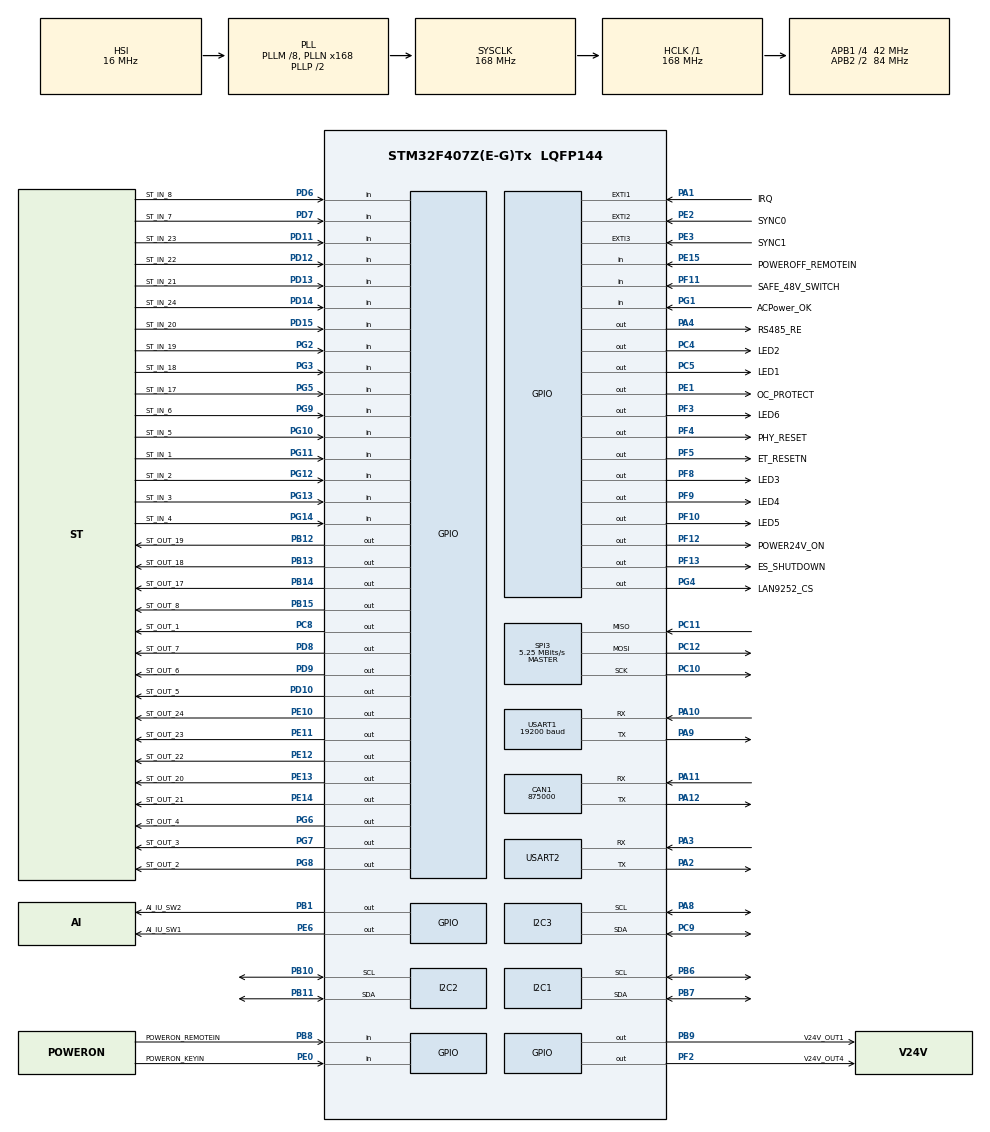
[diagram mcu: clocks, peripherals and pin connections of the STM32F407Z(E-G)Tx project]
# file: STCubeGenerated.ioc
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CAN1.CalculateBaudRate=875000
CAN1.CalculateTimeBit=1142
CAN1.CalculateTimeQuantum=380.95238095238096
Mcu.Family=STM32F4
Mcu.Name=STM32F407Z(E-G)Tx
Mcu.Package=LQFP144
NVIC.CAN1_RX0_IRQn=true\:4\:0\:true\:false\:true\:true\:true
NVIC.EXTI1_IRQn=true\:6\:0\:true\:false\:true\:true\:true
NVIC.EXTI2_IRQn=true\:6\:1\:true\:false\:true\:true\:true
NVIC.EXTI3_IRQn=true\:7\:0\:true\:false\:true\:true\:true
NVIC.PriorityGroup=NVIC_PRIORITYGROUP_3
NVIC.USART1_IRQn=true\:3\:1\:true\:false\:true\:true\:true
NVIC.USART2_IRQn=true\:3\:0\:true\:false\:true\:true\:true
PA1.GPIO_Label=IRQ
PA1.GPIO_ModeDefaultEXTI=GPIO_MODE_IT_FALLING
PA1.Signal=GPXTI1
PA10.GPIO_PuPd=GPIO_NOPULL
PA10.GPIO_Speed=GPIO_SPEED_FREQ_HIGH
PA10.Mode=Asynchronous
PA10.Signal=USART1_RX
PA11.Mode=CAN_Activate
PA11.Signal=CAN1_RX
PA12.Mode=CAN_Activate
PA12.Signal=CAN1_TX
PA2.Mode=Asynchronous
PA2.Signal=USART2_TX
PA3.Mode=Asynchronous
PA3.Signal=USART2_RX
PA4.GPIO_Label=RS485_RE
PA4.GPIO_ModeDefaultOutputPP=GPIO_MODE_OUTPUT_PP
PA4.GPIO_PuPd=GPIO_PULLUP
PA4.GPIO_Speed=GPIO_SPEED_FREQ_VERY_HIGH
PA4.PinState=GPIO_PIN_SET
PA4.Signal=GPIO_Output
PA8.Mode=I2C
PA8.Signal=I2C3_SCL
PA9.GPIO_PuPd=GPIO_NOPULL
PA9.GPIO_Speed=GPIO_SPEED_FREQ_HIGH
PA9.Mode=Asynchronous
PA9.Signal=USART1_TX
PB1.GPIO_Label=AI_IU_SW2
PB1.Signal=GPIO_Output
PB10.Mode=I2C
PB10.Signal=I2C2_SCL
PB11.Mode=I2C
PB11.Signal=I2C2_SDA
PB12.GPIO_Label=ST_OUT_19
PB12.GPIO_ModeDefaultOutputPP=GPIO_MODE_OUTPUT_OD
PB12.GPIO_PuPd=GPIO_NOPULL
PB12.PinState=GPIO_PIN_SET
PB12.Signal=GPIO_Output
PB13.GPIO_Label=ST_OUT_18
PB13.GPIO_ModeDefaultOutputPP=GPIO_MODE_OUTPUT_OD
PB13.GPIO_PuPd=GPIO_NOPULL
PB13.PinState=GPIO_PIN_SET
PB13.Signal=GPIO_Output
PB14.GPIO_Label=ST_OUT_17
PB14.GPIO_ModeDefaultOutputPP=GPIO_MODE_OUTPUT_OD
PB14.GPIO_PuPd=GPIO_NOPULL
PB14.PinState=GPIO_PIN_SET
PB14.Signal=GPIO_Output
PB15.GPIO_Label=ST_OUT_8
PB15.GPIO_ModeDefaultOutputPP=GPIO_MODE_OUTPUT_OD
PB15.GPIO_PuPd=GPIO_NOPULL
PB15.PinState=GPIO_PIN_SET
PB15.Signal=GPIO_Output
PB6.Mode=I2C
PB6.Signal=I2C1_SCL
PB7.Mode=I2C
PB7.Signal=I2C1_SDA
PB8.GPIO_Label=POWERON_REMOTEIN
PB8.Signal=GPIO_Input
PB9.GPIO_Label=V24V_OUT1
PB9.Signal=GPIO_Output
PC10.Mode=Full_Duplex_Master
PC10.Signal=SPI3_SCK
PC11.Mode=Full_Duplex_Master
PC11.Signal=SPI3_MISO
PC12.Mode=Full_Duplex_Master
PC12.Signal=SPI3_MOSI
PC4.GPIO_Label=LED2
PC4.GPIO_ModeDefaultOutputPP=GPIO_MODE_OUTPUT_OD
PC4.GPIO_PuPd=GPIO_NOPULL
PC4.PinState=GPIO_PIN_SET
PC4.Signal=GPIO_Output
PC5.GPIO_Label=LED1
PC5.GPIO_ModeDefaultOutputPP=GPIO_MODE_OUTPUT_OD
PC5.GPIO_PuPd=GPIO_NOPULL
PC5.PinState=GPIO_PIN_SET
PC5.Signal=GPIO_Output
PC8.GPIO_Label=ST_OUT_1
PC8.GPIO_ModeDefaultOutputPP=GPIO_MODE_OUTPUT_OD
PC8.GPIO_PuPd=GPIO_NOPULL
PC8.PinState=GPIO_PIN_SET
PC8.Signal=GPIO_Output
PC9.Mode=I2C
PC9.Signal=I2C3_SDA
PD10.GPIO_Label=ST_OUT_5
PD10.GPIO_ModeDefaultOutputPP=GPIO_MODE_OUTPUT_OD
PD10.GPIO_PuPd=GPIO_NOPULL
PD10.PinState=GPIO_PIN_SET
PD10.Signal=GPIO_Output
PD11.GPIO_Label=ST_IN_23
PD11.Signal=GPIO_Input
PD12.GPIO_Label=ST_IN_22
PD12.Signal=GPIO_Input
PD13.GPIO_Label=ST_IN_21
PD13.Signal=GPIO_Input
PD14.GPIO_Label=ST_IN_24
PD14.Signal=GPIO_Input
PD15.GPIO_Label=ST_IN_20
PD15.Signal=GPIO_Input
PD6.GPIO_Label=ST_IN_8
PD6.Signal=GPIO_Input
PD7.GPIO_Label=ST_IN_7
PD7.Signal=GPIO_Input
PD8.GPIO_Label=ST_OUT_7
PD8.GPIO_ModeDefaultOutputPP=GPIO_MODE_OUTPUT_OD
PD8.GPIO_PuPd=GPIO_NOPULL
PD8.PinState=GPIO_PIN_SET
PD8.Signal=GPIO_Output
PD9.GPIO_Label=ST_OUT_6
PD9.GPIO_ModeDefaultOutputPP=GPIO_MODE_OUTPUT_OD
PD9.GPIO_PuPd=GPIO_NOPULL
PD9.PinState=GPIO_PIN_SET
PD9.Signal=GPIO_Output
PE0.GPIO_Label=POWERON_KEYIN
PE0.Signal=GPIO_Input
PE1.GPIO_Label=OC_PROTECT
PE1.Signal=GPIO_Output
PE10.GPIO_Label=ST_OUT_24
PE10.GPIO_ModeDefaultOutputPP=GPIO_MODE_OUTPUT_OD
PE10.GPIO_PuPd=GPIO_NOPULL
PE10.PinState=GPIO_PIN_SET
PE10.Signal=GPIO_Output
PE11.GPIO_Label=ST_OUT_23
PE11.GPIO_ModeDefaultOutputPP=GPIO_MODE_OUTPUT_OD
PE11.GPIO_PuPd=GPIO_NOPULL
PE11.PinState=GPIO_PIN_SET
PE11.Signal=GPIO_Output
PE12.GPIO_Label=ST_OUT_22
PE12.GPIO_ModeDefaultOutputPP=GPIO_MODE_OUTPUT_OD
PE12.GPIO_PuPd=GPIO_NOPULL
PE12.PinState=GPIO_PIN_SET
PE12.Signal=GPIO_Output
PE13.GPIO_Label=ST_OUT_20
PE13.GPIO_ModeDefaultOutputPP=GPIO_MODE_OUTPUT_OD
PE13.GPIO_PuPd=GPIO_NOPULL
PE13.PinState=GPIO_PIN_SET
PE13.Signal=GPIO_Output
PE14.GPIO_Label=ST_OUT_21
PE14.GPIO_ModeDefaultOutputPP=GPIO_MODE_OUTPUT_OD
PE14.GPIO_PuPd=GPIO_NOPULL
PE14.PinState=GPIO_PIN_SET
PE14.Signal=GPIO_Output
PE15.GPIO_Label=POWEROFF_REMOTEIN
PE15.Signal=GPIO_Input
PE2.GPIO_Label=SYNC0
PE2.GPIO_ModeDefaultEXTI=GPIO_MODE_IT_FALLING
PE2.Signal=GPXTI2
PE3.GPIO_Label=SYNC1
PE3.GPIO_ModeDefaultEXTI=GPIO_MODE_IT_FALLING
PE3.Signal=GPXTI3
PE6.GPIO_Label=AI_IU_SW1
PE6.Signal=GPIO_Output
PF10.GPIO_Label=LED5
PF10.GPIO_ModeDefaultOutputPP=GPIO_MODE_OUTPUT_OD
PF10.GPIO_PuPd=GPIO_NOPULL
PF10.PinState=GPIO_PIN_SET
PF10.Signal=GPIO_Output
PF11.GPIO_Label=SAFE_48V_SWITCH
PF11.Signal=GPIO_Input
PF12.GPIO_Label=POWER24V_ON
PF12.Signal=GPIO_Output
PF13.GPIO_Label=ES_SHUTDOWN
PF13.PinState=GPIO_PIN_SET
PF13.Signal=GPIO_Output
PF2.GPIO_Label=V24V_OUT4
PF2.Signal=GPIO_Output
PF3.GPIO_Label=LED6
PF3.GPIO_ModeDefaultOutputPP=GPIO_MODE_OUTPUT_OD
PF3.GPIO_PuPd=GPIO_NOPULL
PF3.PinState=GPIO_PIN_SET
PF3.Signal=GPIO_Output
PF4.GPIO_Label=PHY_RESET
PF4.GPIO_ModeDefaultOutputPP=GPIO_MODE_OUTPUT_OD
PF4.GPIO_PuPd=GPIO_NOPULL
PF4.PinState=GPIO_PIN_SET
PF4.Signal=GPIO_Output
PF5.GPIO_Label=ET_RESETN
PF5.GPIO_ModeDefaultOutputPP=GPIO_MODE_OUTPUT_OD
PF5.GPIO_PuPd=GPIO_NOPULL
PF5.PinState=GPIO_PIN_SET
PF5.Signal=GPIO_Output
PF8.GPIO_Label=LED3
PF8.GPIO_ModeDefaultOutputPP=GPIO_MODE_OUTPUT_OD
PF8.GPIO_PuPd=GPIO_NOPULL
PF8.PinState=GPIO_PIN_SET
PF8.Signal=GPIO_Output
PF9.GPIO_Label=LED4
PF9.GPIO_ModeDefaultOutputPP=GPIO_MODE_OUTPUT_OD
PF9.GPIO_PuPd=GPIO_NOPULL
PF9.PinState=GPIO_PIN_SET
PF9.Signal=GPIO_Output
PG1.GPIO_Label=ACPower_OK
PG1.Signal=GPIO_Input
PG10.GPIO_Label=ST_IN_5
PG10.Signal=GPIO_Input
PG11.GPIO_Label=ST_IN_1
PG11.Signal=GPIO_Input
PG12.GPIO_Label=ST_IN_2
PG12.Signal=GPIO_Input
PG13.GPIO_Label=ST_IN_3
PG13.Signal=GPIO_Input
PG14.GPIO_Label=ST_IN_4
PG14.Signal=GPIO_Input
PG2.GPIO_Label=ST_IN_19
PG2.Signal=GPIO_Input
PG3.GPIO_Label=ST_IN_18
PG3.Signal=GPIO_Input
PG4.GPIO_Label=LAN9252_CS
PG4.GPIO_PuPd=GPIO_PULLUP
PG4.GPIO_Speed=GPIO_SPEED_FREQ_VERY_HIGH
PG4.PinState=GPIO_PIN_SET
PG4.Signal=GPIO_Output
PG5.GPIO_Label=ST_IN_17
PG5.Signal=GPIO_Input
PG6.GPIO_Label=ST_OUT_4
PG6.GPIO_ModeDefaultOutputPP=GPIO_MODE_OUTPUT_OD
PG6.GPIO_PuPd=GPIO_NOPULL
PG6.PinState=GPIO_PIN_SET
PG6.Signal=GPIO_Output
PG7.GPIO_Label=ST_OUT_3
PG7.GPIO_ModeDefaultOutputPP=GPIO_MODE_OUTPUT_OD
PG7.GPIO_PuPd=GPIO_NOPULL
PG7.PinState=GPIO_PIN_SET
PG7.Signal=GPIO_Output
PG8.GPIO_Label=ST_OUT_2
PG8.GPIO_ModeDefaultOutputPP=GPIO_MODE_OUTPUT_OD
PG8.GPIO_PuPd=GPIO_NOPULL
PG8.PinState=GPIO_PIN_SET
PG8.Signal=GPIO_Output
PG9.GPIO_Label=ST_IN_6
PG9.Signal=GPIO_Input
PH0-OSC_IN.Mode=HSE-External-Oscillator
PH0-OSC_IN.Signal=RCC_OSC_IN
PH1-OSC_OUT.Mode=HSE-External-Oscillator
PH1-OSC_OUT.Signal=RCC_OSC_OUT
ProjectManager.HeapSize=0x200
ProjectManager.StackSize=0x400
ProjectManager.TargetToolchain=MDK-ARM V5
RCC.48MHZClocksFreq_Value=84000000
RCC.AHBFreq_Value=168000000
RCC.APB1CLKDivider=RCC_HCLK_DIV4
RCC.APB1Freq_Value=42000000
RCC.APB1TimFreq_Value=84000000
RCC.APB2CLKDivider=RCC_HCLK_DIV2
RCC.APB2Freq_Value=84000000
RCC.APB2TimFreq_Value=168000000
RCC.CortexFreq_Value=168000000
RCC.HCLKFreq_Value=168000000
RCC.HSE_VALUE=8000000
RCC.HSI_VALUE=16000000
RCC.LSE_VALUE=32768
RCC.PLLM=8
RCC.PLLN=168
RCC.SYSCLKFreq_VALUE=168000000
RCC.SYSCLKSource=RCC_SYSCLKSOURCE_PLLCLK
RCC.VCOOutputFreq_Value=336000000
SPI3.BaudRatePrescaler=SPI_BAUDRATEPRESCALER_8
SPI3.CLKPhase=SPI_PHASE_1EDGE
SPI3.CLKPolarity=SPI_POLARITY_LOW
SPI3.CalculateBaudRate=5.25 MBits/s
SPI3.DataSize=SPI_DATASIZE_8BIT
SPI3.Direction=SPI_DIRECTION_2LINES
SPI3.Mode=SPI_MODE_MASTER
SPI3.TIMode=SPI_TIMODE_DISABLE
SPI3.VirtualType=VM_MASTER
USART1.BaudRate=19200
USART1.VirtualMode=VM_ASYNC
USART2.VirtualMode=VM_ASYNC
board=custom

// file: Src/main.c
/* USER CODE BEGIN Header */
/**
  ******************************************************************************
  * @file           : main.c
  * @brief          : Main program body
  ******************************************************************************
  * @attention
  *
  * Copyright (c) 2022 STMicroelectronics.
  * All rights reserved.
  *
  * This software is licensed under terms that can be found in the LICENSE file
  * in the root directory of this software component.
  * If no LICENSE file comes with this software, it is provided AS-IS.
  *
  ******************************************************************************
  */
/* USER CODE END Header */
#include "main.h"

/* USER CODE BEGIN Includes */
#include "ADS1115Driver.h"
#include "Command.h"
#include "KeyIn.h"
#include "PowerMenu.h"
#include "KeyIn.h"

/* USER CODE END Includes */

CAN_HandleTypeDef hcan1;

I2C_HandleTypeDef hi2c1;
I2C_HandleTypeDef hi2c2;
I2C_HandleTypeDef hi2c3;

SPI_HandleTypeDef hspi3;

UART_HandleTypeDef huart1;
UART_HandleTypeDef huart2;

void SystemClock_Config(void);
static void MX_GPIO_Init(void);
static void MX_SPI3_Init(void);
static void MX_CAN1_Init(void);
static void MX_I2C1_Init(void);
static void MX_I2C2_Init(void);
static void MX_I2C3_Init(void);
static void MX_USART1_UART_Init(void);
static void MX_USART2_UART_Init(void);
/* USER CODE BEGIN PFP */

void PHY_Init(void);
/* USER CODE END PFP */

int main(void)
{

  /* MCU Configuration--------------------------------------------------------*/

  /* Reset of all peripherals, Initializes the Flash interface and the Systick. */
  HAL_Init();

  /* Configure the system clock */
  SystemClock_Config();

  /* Initialize all configured peripherals */
  MX_GPIO_Init();
  MX_SPI3_Init();
  MX_CAN1_Init();
  MX_I2C1_Init();
  MX_I2C2_Init();
  MX_I2C3_Init();
  MX_USART1_UART_Init();
  MX_USART2_UART_Init();
  /* USER CODE BEGIN 2 */
    EcatHspiPtr = &hspi3;
		I2C_Ptr_24V = &hi2c1;
		I2C_Ptr_48V_NTC = &hi2c3;
		I2C_Ptr_AI = &hi2c2;
		Uart_HandlePtr = &huart1;
//		Udma_UartRx_HandlePtr = &hdma_usart1_rx;
//		Udma_Uarttx_HandlePtr = &hdma_usart1_tx;
//    LAN9252_Init();
//    MainInit();
//    bRunApplication = TRUE;
//		PHY_Init();
//		HAL_GPIO_WritePin(OC_PROTECT_GPIO_Port, OC_PROTECT_Pin, GPIO_PIN_RESET);
//		HAL_GPIO_WritePin(V24V_OUT1_GPIO_Port, V24V_OUT1_Pin, GPIO_PIN_SET);
//		HAL_GPIO_WritePin(ES_SHUTDOWN_GPIO_Port, ES_SHUTDOWN_Pin, GPIO_PIN_SET);
		if (HAL_UARTEx_ReceiveToIdle_IT(&huart1, PowerCommandRxBuffer, POWER_COMMAND_TXRX_BUFFER_SIZE) != HAL_OK)
		{
			Error_Handler();
		}
		ADS1115_Driver_Initilization();
		Power_Command_Initilization();
  /* USER CODE END 2 */

  /* Infinite loop */
  /* USER CODE BEGIN WHILE */
  while (1)
  {
//		MainLoop();
	  work_mode_operation();
		ADS1115_Driver_MainLoop();
		KeyScan(power_manage.work_mode);
		Power_Command_Main_Loop();

    /* USER CODE END WHILE */

  }
}

void SystemClock_Config(void)
{
  RCC_OscInitTypeDef RCC_OscInitStruct = {0};
  RCC_ClkInitTypeDef RCC_ClkInitStruct = {0};

  /** Configure the main internal regulator output voltage
  */
  __HAL_RCC_PWR_CLK_ENABLE();
  __HAL_PWR_VOLTAGESCALING_CONFIG(PWR_REGULATOR_VOLTAGE_SCALE1);
  /** Initializes the RCC Oscillators according to the specified parameters
  * in the RCC_OscInitTypeDef structure.
  */
  RCC_OscInitStruct.OscillatorType = RCC_OSCILLATORTYPE_HSI;
  RCC_OscInitStruct.HSIState = RCC_HSI_ON;
  RCC_OscInitStruct.HSICalibrationValue = RCC_HSICALIBRATION_DEFAULT;
  RCC_OscInitStruct.PLL.PLLState = RCC_PLL_ON;
  RCC_OscInitStruct.PLL.PLLSource = RCC_PLLSOURCE_HSI;
  RCC_OscInitStruct.PLL.PLLM = 8;
  RCC_OscInitStruct.PLL.PLLN = 168;
  RCC_OscInitStruct.PLL.PLLP = RCC_PLLP_DIV2;
  RCC_OscInitStruct.PLL.PLLQ = 4;
  if (HAL_RCC_OscConfig(&RCC_OscInitStruct) != HAL_OK)
  {
    Error_Handler();
  }
  /** Initializes the CPU, AHB and APB buses clocks
  */
  RCC_ClkInitStruct.ClockType = RCC_CLOCKTYPE_HCLK|RCC_CLOCKTYPE_SYSCLK
                              |RCC_CLOCKTYPE_PCLK1|RCC_CLOCKTYPE_PCLK2;
  RCC_ClkInitStruct.SYSCLKSource = RCC_SYSCLKSOURCE_PLLCLK;
  RCC_ClkInitStruct.AHBCLKDivider = RCC_SYSCLK_DIV1;
  RCC_ClkInitStruct.APB1CLKDivider = RCC_HCLK_DIV4;
  RCC_ClkInitStruct.APB2CLKDivider = RCC_HCLK_DIV2;

  if (HAL_RCC_ClockConfig(&RCC_ClkInitStruct, FLASH_LATENCY_5) != HAL_OK)
  {
    Error_Handler();
  }
}

static void MX_CAN1_Init(void)
{

  hcan1.Instance = CAN1;
  hcan1.Init.Prescaler = 16;
  hcan1.Init.Mode = CAN_MODE_NORMAL;
  hcan1.Init.SyncJumpWidth = CAN_SJW_1TQ;
  hcan1.Init.TimeSeg1 = CAN_BS1_1TQ;
  hcan1.Init.TimeSeg2 = CAN_BS2_1TQ;
  hcan1.Init.TimeTriggeredMode = DISABLE;
  hcan1.Init.AutoBusOff = DISABLE;
  hcan1.Init.AutoWakeUp = DISABLE;
  hcan1.Init.AutoRetransmission = DISABLE;
  hcan1.Init.ReceiveFifoLocked = DISABLE;
  hcan1.Init.TransmitFifoPriority = DISABLE;
  if (HAL_CAN_Init(&hcan1) != HAL_OK)
  {
    Error_Handler();
  }

}

static void MX_I2C1_Init(void)
{

  hi2c1.Instance = I2C1;
  hi2c1.Init.ClockSpeed = 100000;
  hi2c1.Init.DutyCycle = I2C_DUTYCYCLE_2;
  hi2c1.Init.OwnAddress1 = 0;
  hi2c1.Init.AddressingMode = I2C_ADDRESSINGMODE_7BIT;
  hi2c1.Init.DualAddressMode = I2C_DUALADDRESS_DISABLE;
  hi2c1.Init.OwnAddress2 = 0;
  hi2c1.Init.GeneralCallMode = I2C_GENERALCALL_DISABLE;
  hi2c1.Init.NoStretchMode = I2C_NOSTRETCH_DISABLE;
  if (HAL_I2C_Init(&hi2c1) != HAL_OK)
  {
    Error_Handler();
  }

}

static void MX_I2C2_Init(void)
{

  hi2c2.Instance = I2C2;
  hi2c2.Init.ClockSpeed = 100000;
  hi2c2.Init.DutyCycle = I2C_DUTYCYCLE_2;
  hi2c2.Init.OwnAddress1 = 0;
  hi2c2.Init.AddressingMode = I2C_ADDRESSINGMODE_7BIT;
  hi2c2.Init.DualAddressMode = I2C_DUALADDRESS_DISABLE;
  hi2c2.Init.OwnAddress2 = 0;
  hi2c2.Init.GeneralCallMode = I2C_GENERALCALL_DISABLE;
  hi2c2.Init.NoStretchMode = I2C_NOSTRETCH_DISABLE;
  if (HAL_I2C_Init(&hi2c2) != HAL_OK)
  {
    Error_Handler();
  }

}

static void MX_I2C3_Init(void)
{

  hi2c3.Instance = I2C3;
  hi2c3.Init.ClockSpeed = 100000;
  hi2c3.Init.DutyCycle = I2C_DUTYCYCLE_2;
  hi2c3.Init.OwnAddress1 = 0;
  hi2c3.Init.AddressingMode = I2C_ADDRESSINGMODE_7BIT;
  hi2c3.Init.DualAddressMode = I2C_DUALADDRESS_DISABLE;
  hi2c3.Init.OwnAddress2 = 0;
  hi2c3.Init.GeneralCallMode = I2C_GENERALCALL_DISABLE;
  hi2c3.Init.NoStretchMode = I2C_NOSTRETCH_DISABLE;
  if (HAL_I2C_Init(&hi2c3) != HAL_OK)
  {
    Error_Handler();
  }

}

static void MX_SPI3_Init(void)
{

  /* SPI3 parameter configuration*/
  hspi3.Instance = SPI3;
  hspi3.Init.Mode = SPI_MODE_MASTER;
  hspi3.Init.Direction = SPI_DIRECTION_2LINES;
  hspi3.Init.DataSize = SPI_DATASIZE_8BIT;
  hspi3.Init.CLKPolarity = SPI_POLARITY_LOW;
  hspi3.Init.CLKPhase = SPI_PHASE_1EDGE;
  hspi3.Init.NSS = SPI_NSS_SOFT;
  hspi3.Init.BaudRatePrescaler = SPI_BAUDRATEPRESCALER_8;
  hspi3.Init.FirstBit = SPI_FIRSTBIT_MSB;
  hspi3.Init.TIMode = SPI_TIMODE_DISABLE;
  hspi3.Init.CRCCalculation = SPI_CRCCALCULATION_DISABLE;
  hspi3.Init.CRCPolynomial = 10;
  if (HAL_SPI_Init(&hspi3) != HAL_OK)
  {
    Error_Handler();
  }
  /* USER CODE BEGIN SPI3_Init 2 */
//	hspi3.pTxBuffPtr = EcatSpiWriteBuffer;
//	hspi3.pRxBuffPtr = EcatSpiReadBuffer;
//	hspi3.RxXferSize = SPI_BUFFER_SIZE;
//	hspi3.TxXferSize = SPI_BUFFER_SIZE;
//	hspi3.RxXferCount = 0u;
//	hspi3.TxXferCount = 0u;
  /* USER CODE END SPI3_Init 2 */

}

static void MX_USART1_UART_Init(void)
{

  huart1.Instance = USART1;
  huart1.Init.BaudRate = 19200;
  huart1.Init.WordLength = UART_WORDLENGTH_8B;
  huart1.Init.StopBits = UART_STOPBITS_1;
  huart1.Init.Parity = UART_PARITY_NONE;
  huart1.Init.Mode = UART_MODE_TX_RX;
  huart1.Init.HwFlowCtl = UART_HWCONTROL_NONE;
  huart1.Init.OverSampling = UART_OVERSAMPLING_16;
  if (HAL_UART_Init(&huart1) != HAL_OK)
  {
    Error_Handler();
  }

}

static void MX_USART2_UART_Init(void)
{

  huart2.Instance = USART2;
  huart2.Init.BaudRate = 115200;
  huart2.Init.WordLength = UART_WORDLENGTH_8B;
  huart2.Init.StopBits = UART_STOPBITS_1;
  huart2.Init.Parity = UART_PARITY_NONE;
  huart2.Init.Mode = UART_MODE_TX_RX;
  huart2.Init.HwFlowCtl = UART_HWCONTROL_NONE;
  huart2.Init.OverSampling = UART_OVERSAMPLING_16;
  if (HAL_UART_Init(&huart2) != HAL_OK)
  {
    Error_Handler();
  }

}

static void MX_GPIO_Init(void)
{
  GPIO_InitTypeDef GPIO_InitStruct = {0};

  /* GPIO Ports Clock Enable */
  __HAL_RCC_GPIOE_CLK_ENABLE();
  __HAL_RCC_GPIOF_CLK_ENABLE();
  __HAL_RCC_GPIOH_CLK_ENABLE();
  __HAL_RCC_GPIOA_CLK_ENABLE();
  __HAL_RCC_GPIOC_CLK_ENABLE();
  __HAL_RCC_GPIOB_CLK_ENABLE();
  __HAL_RCC_GPIOG_CLK_ENABLE();
  __HAL_RCC_GPIOD_CLK_ENABLE();

  /*Configure GPIO pin Output Level */
  HAL_GPIO_WritePin(GPIOE, AI_IU_SW1_Pin|OC_PROTECT_Pin, GPIO_PIN_RESET);

  /*Configure GPIO pin Output Level */
  HAL_GPIO_WritePin(GPIOF, V24V_OUT4_Pin|POWER24V_ON_Pin, GPIO_PIN_RESET);

  /*Configure GPIO pin Output Level */
  HAL_GPIO_WritePin(GPIOF, LED6_Pin|PHY_RESET_Pin|ET_RESETN_Pin|LED3_Pin
                          |LED4_Pin|LED5_Pin|ES_SHUTDOWN_Pin, GPIO_PIN_SET);

  /*Configure GPIO pin Output Level */
  HAL_GPIO_WritePin(RS485_RE_GPIO_Port, RS485_RE_Pin, GPIO_PIN_SET);

  /*Configure GPIO pin Output Level */
  HAL_GPIO_WritePin(GPIOC, LED2_Pin|LED1_Pin|ST_OUT_1_Pin, GPIO_PIN_SET);

  /*Configure GPIO pin Output Level */
  HAL_GPIO_WritePin(GPIOB, AI_IU_SW2_Pin|V24V_OUT1_Pin, GPIO_PIN_RESET);

  /*Configure GPIO pin Output Level */
  HAL_GPIO_WritePin(GPIOE, ST_OUT_24_Pin|ST_OUT_23_Pin|ST_OUT_22_Pin|ST_OUT_20_Pin
                          |ST_OUT_21_Pin, GPIO_PIN_SET);

  /*Configure GPIO pin Output Level */
  HAL_GPIO_WritePin(GPIOB, ST_OUT_19_Pin|ST_OUT_18_Pin|ST_OUT_17_Pin|ST_OUT_8_Pin, GPIO_PIN_SET);

  /*Configure GPIO pin Output Level */
  HAL_GPIO_WritePin(GPIOD, ST_OUT_7_Pin|ST_OUT_6_Pin|ST_OUT_5_Pin, GPIO_PIN_SET);

  /*Configure GPIO pin Output Level */
  HAL_GPIO_WritePin(GPIOG, LAN9252_CS_Pin|ST_OUT_4_Pin|ST_OUT_3_Pin|ST_OUT_2_Pin, GPIO_PIN_SET);

  /*Configure GPIO pins : SYNC0_Pin SYNC1_Pin */
  GPIO_InitStruct.Pin = SYNC0_Pin|SYNC1_Pin;
  GPIO_InitStruct.Mode = GPIO_MODE_IT_FALLING;
  GPIO_InitStruct.Pull = GPIO_NOPULL;
  HAL_GPIO_Init(GPIOE, &GPIO_InitStruct);

  /*Configure GPIO pins : AI_IU_SW1_Pin OC_PROTECT_Pin */
  GPIO_InitStruct.Pin = AI_IU_SW1_Pin|OC_PROTECT_Pin;
  GPIO_InitStruct.Mode = GPIO_MODE_OUTPUT_PP;
  GPIO_InitStruct.Pull = GPIO_NOPULL;
  GPIO_InitStruct.Speed = GPIO_SPEED_FREQ_LOW;
  HAL_GPIO_Init(GPIOE, &GPIO_InitStruct);

  /*Configure GPIO pins : V24V_OUT4_Pin POWER24V_ON_Pin ES_SHUTDOWN_Pin */
  GPIO_InitStruct.Pin = V24V_OUT4_Pin|POWER24V_ON_Pin|ES_SHUTDOWN_Pin;
  GPIO_InitStruct.Mode = GPIO_MODE_OUTPUT_PP;
  GPIO_InitStruct.Pull = GPIO_NOPULL;
  GPIO_InitStruct.Speed = GPIO_SPEED_FREQ_LOW;
  HAL_GPIO_Init(GPIOF, &GPIO_InitStruct);

  /*Configure GPIO pins : LED6_Pin PHY_RESET_Pin ET_RESETN_Pin LED3_Pin
                           LED4_Pin LED5_Pin */
  GPIO_InitStruct.Pin = LED6_Pin|PHY_RESET_Pin|ET_RESETN_Pin|LED3_Pin
                          |LED4_Pin|LED5_Pin;
  GPIO_InitStruct.Mode = GPIO_MODE_OUTPUT_OD;
  GPIO_InitStruct.Pull = GPIO_NOPULL;
  GPIO_InitStruct.Speed = GPIO_SPEED_FREQ_LOW;
  HAL_GPIO_Init(GPIOF, &GPIO_InitStruct);

  /*Configure GPIO pin : IRQ_Pin */
  GPIO_InitStruct.Pin = IRQ_Pin;
  GPIO_InitStruct.Mode = GPIO_MODE_IT_FALLING;
  GPIO_InitStruct.Pull = GPIO_NOPULL;
  HAL_GPIO_Init(IRQ_GPIO_Port, &GPIO_InitStruct);

  /*Configure GPIO pin : RS485_RE_Pin */
  GPIO_InitStruct.Pin = RS485_RE_Pin;
  GPIO_InitStruct.Mode = GPIO_MODE_OUTPUT_PP;
  GPIO_InitStruct.Pull = GPIO_PULLUP;
  GPIO_InitStruct.Speed = GPIO_SPEED_FREQ_VERY_HIGH;
  HAL_GPIO_Init(RS485_RE_GPIO_Port, &GPIO_InitStruct);

  /*Configure GPIO pins : LED2_Pin LED1_Pin ST_OUT_1_Pin */
  GPIO_InitStruct.Pin = LED2_Pin|LED1_Pin|ST_OUT_1_Pin;
  GPIO_InitStruct.Mode = GPIO_MODE_OUTPUT_OD;
  GPIO_InitStruct.Pull = GPIO_NOPULL;
  GPIO_InitStruct.Speed = GPIO_SPEED_FREQ_LOW;
  HAL_GPIO_Init(GPIOC, &GPIO_InitStruct);

  /*Configure GPIO pins : AI_IU_SW2_Pin V24V_OUT1_Pin */
  GPIO_InitStruct.Pin = AI_IU_SW2_Pin|V24V_OUT1_Pin;
  GPIO_InitStruct.Mode = GPIO_MODE_OUTPUT_PP;
  GPIO_InitStruct.Pull = GPIO_NOPULL;
  GPIO_InitStruct.Speed = GPIO_SPEED_FREQ_LOW;
  HAL_GPIO_Init(GPIOB, &GPIO_InitStruct);

  /*Configure GPIO pin : SAFE_48V_SWITCH_Pin */
  GPIO_InitStruct.Pin = SAFE_48V_SWITCH_Pin;
  GPIO_InitStruct.Mode = GPIO_MODE_INPUT;
  GPIO_InitStruct.Pull = GPIO_NOPULL;
  HAL_GPIO_Init(SAFE_48V_SWITCH_GPIO_Port, &GPIO_InitStruct);

  /*Configure GPIO pins : ACPower_OK_Pin ST_IN_19_Pin ST_IN_18_Pin ST_IN_17_Pin
                           ST_IN_6_Pin ST_IN_5_Pin ST_IN_1_Pin ST_IN_2_Pin
                           ST_IN_3_Pin ST_IN_4_Pin */
  GPIO_InitStruct.Pin = ACPower_OK_Pin|ST_IN_19_Pin|ST_IN_18_Pin|ST_IN_17_Pin
                          |ST_IN_6_Pin|ST_IN_5_Pin|ST_IN_1_Pin|ST_IN_2_Pin
                          |ST_IN_3_Pin|ST_IN_4_Pin;
  GPIO_InitStruct.Mode = GPIO_MODE_INPUT;
  GPIO_InitStruct.Pull = GPIO_NOPULL;
  HAL_GPIO_Init(GPIOG, &GPIO_InitStruct);

  /*Configure GPIO pins : ST_OUT_24_Pin ST_OUT_23_Pin ST_OUT_22_Pin ST_OUT_20_Pin
                           ST_OUT_21_Pin */
  GPIO_InitStruct.Pin = ST_OUT_24_Pin|ST_OUT_23_Pin|ST_OUT_22_Pin|ST_OUT_20_Pin
                          |ST_OUT_21_Pin;
  GPIO_InitStruct.Mode = GPIO_MODE_OUTPUT_OD;
  GPIO_InitStruct.Pull = GPIO_NOPULL;
  GPIO_InitStruct.Speed = GPIO_SPEED_FREQ_LOW;
  HAL_GPIO_Init(GPIOE, &GPIO_InitStruct);

  /*Configure GPIO pins : POWEROFF_REMOTEIN_Pin POWERON_KEYIN_Pin */
  GPIO_InitStruct.Pin = POWEROFF_REMOTEIN_Pin|POWERON_KEYIN_Pin;
  GPIO_InitStruct.Mode = GPIO_MODE_INPUT;
  GPIO_InitStruct.Pull = GPIO_NOPULL;
  HAL_GPIO_Init(GPIOE, &GPIO_InitStruct);

  /*Configure GPIO pins : ST_OUT_19_Pin ST_OUT_18_Pin ST_OUT_17_Pin ST_OUT_8_Pin */
  GPIO_InitStruct.Pin = ST_OUT_19_Pin|ST_OUT_18_Pin|ST_OUT_17_Pin|ST_OUT_8_Pin;
  GPIO_InitStruct.Mode = GPIO_MODE_OUTPUT_OD;
  GPIO_InitStruct.Pull = GPIO_NOPULL;
  GPIO_InitStruct.Speed = GPIO_SPEED_FREQ_LOW;
  HAL_GPIO_Init(GPIOB, &GPIO_InitStruct);

  /*Configure GPIO pins : ST_OUT_7_Pin ST_OUT_6_Pin ST_OUT_5_Pin */
  GPIO_InitStruct.Pin = ST_OUT_7_Pin|ST_OUT_6_Pin|ST_OUT_5_Pin;
  GPIO_InitStruct.Mode = GPIO_MODE_OUTPUT_OD;
  GPIO_InitStruct.Pull = GPIO_NOPULL;
  GPIO_InitStruct.Speed = GPIO_SPEED_FREQ_LOW;
  HAL_GPIO_Init(GPIOD, &GPIO_InitStruct);

  /*Configure GPIO pins : ST_IN_23_Pin ST_IN_22_Pin ST_IN_21_Pin ST_IN_24_Pin
                           ST_IN_20_Pin ST_IN_8_Pin ST_IN_7_Pin */
  GPIO_InitStruct.Pin = ST_IN_23_Pin|ST_IN_22_Pin|ST_IN_21_Pin|ST_IN_24_Pin
                          |ST_IN_20_Pin|ST_IN_8_Pin|ST_IN_7_Pin;
  GPIO_InitStruct.Mode = GPIO_MODE_INPUT;
  GPIO_InitStruct.Pull = GPIO_NOPULL;
  HAL_GPIO_Init(GPIOD, &GPIO_InitStruct);

  /*Configure GPIO pin : LAN9252_CS_Pin */
  GPIO_InitStruct.Pin = LAN9252_CS_Pin;
  GPIO_InitStruct.Mode = GPIO_MODE_OUTPUT_PP;
  GPIO_InitStruct.Pull = GPIO_PULLUP;
  GPIO_InitStruct.Speed = GPIO_SPEED_FREQ_VERY_HIGH;
  HAL_GPIO_Init(LAN9252_CS_GPIO_Port, &GPIO_InitStruct);

  /*Configure GPIO pins : ST_OUT_4_Pin ST_OUT_3_Pin ST_OUT_2_Pin */
  GPIO_InitStruct.Pin = ST_OUT_4_Pin|ST_OUT_3_Pin|ST_OUT_2_Pin;
  GPIO_InitStruct.Mode = GPIO_MODE_OUTPUT_OD;
  GPIO_InitStruct.Pull = GPIO_NOPULL;
  GPIO_InitStruct.Speed = GPIO_SPEED_FREQ_LOW;
  HAL_GPIO_Init(GPIOG, &GPIO_InitStruct);

  /*Configure GPIO pin : POWERON_REMOTEIN_Pin */
  GPIO_InitStruct.Pin = POWERON_REMOTEIN_Pin;
  GPIO_InitStruct.Mode = GPIO_MODE_INPUT;
  GPIO_InitStruct.Pull = GPIO_NOPULL;
  HAL_GPIO_Init(POWERON_REMOTEIN_GPIO_Port, &GPIO_InitStruct);

  /* EXTI interrupt init*/
  HAL_NVIC_SetPriority(EXTI1_IRQn, 6, 0);
  HAL_NVIC_EnableIRQ(EXTI1_IRQn);

  HAL_NVIC_SetPriority(EXTI2_IRQn, 6, 1);
  HAL_NVIC_EnableIRQ(EXTI2_IRQn);

  HAL_NVIC_SetPriority(EXTI3_IRQn, 7, 0);
  HAL_NVIC_EnableIRQ(EXTI3_IRQn);

}

/* USER CODE BEGIN 4 */
void PHY_Init(void)
{
	uint32_t startTime;
	uint32_t nowTime;
	uint32_t elapseTime;

	startTime = HAL_GetTick();
	elapseTime = 0u;
	GPIOF->ODR &= 0xffefu;

	while(elapseTime <= 1u)
	{
		nowTime = HAL_GetTick();
		elapseTime = nowTime - startTime;
	}

	GPIOF->ODR |= ((uint32_t)1u << 4u);
}
/* USER CODE END 4 */

void Error_Handler(void)
{
  __disable_irq();
  while (1)
  {
  }
}
